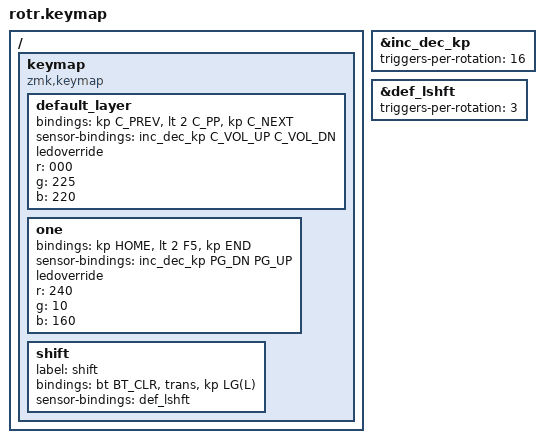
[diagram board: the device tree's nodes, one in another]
#include <behaviors.dtsi>
#include <dt-bindings/zmk/keys.h>
#include <dt-bindings/zmk/rgb.h>
#include <dt-bindings/zmk/bt.h>

&inc_dec_kp {
	triggers-per-rotation = <16>;
};
&def_lshft {
	triggers-per-rotation = <3>;
};

/ {
	keymap {
		compatible = "zmk,keymap";

		default_layer {
			// PREV | PLAY/PAUSE | NEXT
			bindings = <&kp C_PREV &lt 2 C_PP &kp C_NEXT>;
			sensor-bindings = <&inc_dec_kp C_VOL_UP C_VOL_DN>;
			ledoverride;
			r = <000>;
        		g = <225>;
			b = <220>;
		};
		one {
			// HOME | F5 / REFRESH | END
			bindings = <&kp HOME &lt 2 F5 &kp END>;
			sensor-bindings = <&inc_dec_kp PG_DN PG_UP>;
			ledoverride;
			r = <240>;
        		g = <10>;
			b = <160>;
		};
		shift {
			label = "shift";
			//
			bindings = <&bt BT_CLR &trans &kp LG(L)>;
			sensor-bindings = <&def_lshft>;
		};
	};
};

